# NM1500_v1 register map
File version: 1.0
Registers are 32-bit, read-write, reset 0x0 unless marked. A register's access mark holds for its fields unless they carry their own. Offsets are from the block's base; [hi:lo] are bit positions; {n}, {i} and the like mark numbered series; 'fields as' and 'values as' point back to an identical list.

## ADC — ADC Register Map
Base 0x400E0000
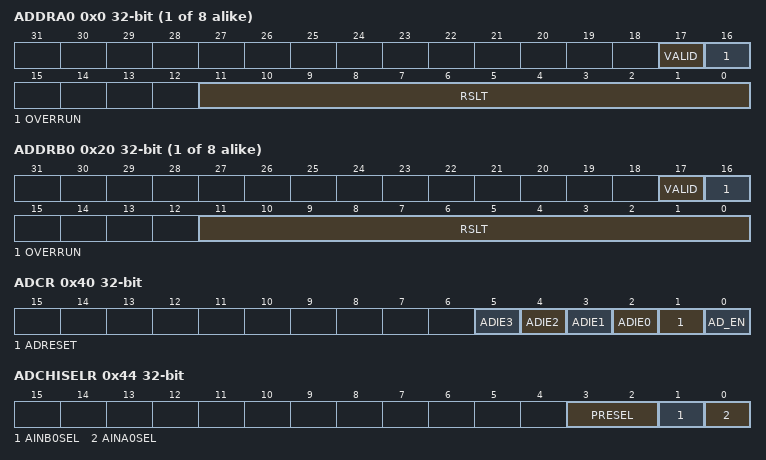
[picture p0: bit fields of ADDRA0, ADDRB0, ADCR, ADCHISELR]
{0x0+4i} ADDRA{i} ro (i=0..7) — A/D Data Register 0 for SAMPLEA0
  [17] VALID — Valid Flag. This bit is set to 1 when corresponding SAMPLE channel analog input conversion is completed and cleared by hardware after ADDR register is read.
    0=Data in RSLT[11:0] bits is not valid; 1=Data in RSLT[11:0] bits is valid
  [16] OVERRUN — Over Run Flag. If converted data in RSLT[11:0] has not been read before new conversion result is loaded to this register, OVERRUN is set to 1. It is cleared by hardware after ADDR register is read.
    0=Data in RSLT[11:0] is the recent conversion result; 1=Data in RSLT[11:0] is overwritten
  [11:0] RSLT — A/D Conversion Result. This field contains 12-bit conversion result.
{0x20+4i} ADDRB{i} ro (i=0..7) — A/D Data Register 0 for SAMPLEA0
  fields as ADDRA0
0x40 ADCR — A/D Control Register
  [n+2] ADIE{n} (n=0..3) — Specific SAMPLE A/D ADINT{n} Interrupt Enable. The A/D converter generates a conversion end ADF{n} flag in ADSR1 register upon the end of specific SAMPLE A/D conversion. If ADIE{n} bit is set then conversion end interrupt request ADINT{n} is generated.
    0=Specific SAMPLE A/D ADINT{n} interrupt function Disabled; 1=Specific SAMPLE A/D ADINT{n} interrupt function Enabled
  [1] ADRESET — ADCA, ADCB A/D Converter control circuits reset. ADRESET bit remains 1 during ADC reset, when ADC reset end, the ADRESET bit is automatically cleared to 0.
    0=Writing 0 has no effect; 1=Writing 1 will cause ADC control circuits reset to initial state, but not change the ADC registers value
  [0] AD_EN — A/D Converter Enable. Before starting the A/D conversion function, this bit should be set to 1. Clear it to 0 to disable A/D converter analog circuit power consumption.
    0=Disabled; 1=Enabled
0x44 ADCHISELR — A/D Channel Input Sources Select Register
  [3:2] PRESEL — A/D Channel AINA[7] Analog Input Selection
    0=Analog Input Channel AINA7; 1=Band-gap (VBG) Analog Input; 2=VTEMP Internal Temperature Sensor Analog Input; 3=Analog ground
  [1] AINB0SEL — A/D Channel AINB[0] Analog Input Selection
    0=AINB[0] pin P7.0/AINB0 is selected as the A/D AINB[0] input signal; 1=OP Amplifier 1 output is selected as the A/D AINB[0] input signal
  [0] AINA0SEL — A/D Channel AINA[0] Analog Input Selection
    0=AINA[0] pin P6.0/AINA0 is selected as the ADC AINA[0] input signal; 1=OP Amplifier 0 output is selected as the ADC AINA[0] input signal
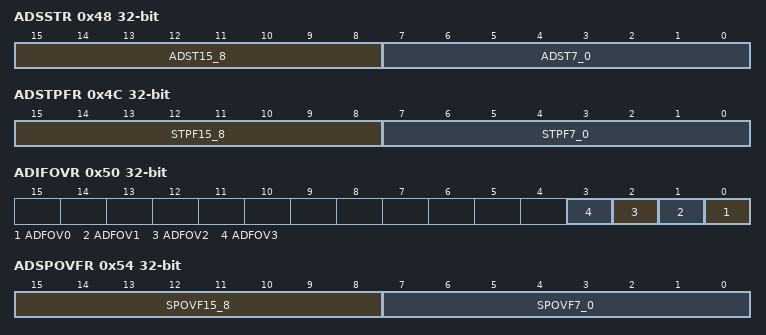
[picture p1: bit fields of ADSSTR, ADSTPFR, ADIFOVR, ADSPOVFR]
0x48 ADSSTR wo — A/D SAMPLE Software Start Register
  [15:8] ADST15_8 — A/D SAMPLEB7~0 Software Force to Start ADC Conversion Register
    0=No effect; 1=Cause an ADC conversion when the priority is given to SAMPLEB
  [7:0] ADST7_0 — A/D SAMPLEA7~0 Software Force to Start ADC Conversion Register
    0=No effect; 1=Cause an ADC conversion when the priority is given to SAMPLEA
0x4C ADSTPFR ro — A/D SAMPLE Start of Conversion Pending Flag Register
  [15:8] STPF15_8 — A/D SAMPLEB7~0 Start Conversion Pending Flag. This bit remains 1 during pending state, when the respective ADC conversion is started, the STPFx bit is automatically cleared to 0.
    0=No pending conversion for SAMPLEB; 1=SAMPLEB ADC start of conversion is pending
  [7:0] STPF7_0 — A/D SAMPLEA7~0 Start Conversion Pending Flag. This bit remains 1 during pending state, when the respective ADC conversion is started, the STPFx bit is automatically cleared to 0.
    0=There is no pending conversion for SAMPLEA; 1=SAMPLEA ADC start of conversion is pending
0x50 ADIFOVR — A/D ADINT3~0 Interrupt Flag Over Run Register
  [n] ADFOV{n} (n=0..3) — A/D ADINT{n} Interrupt flag over run bit. It is cleared by write 1.
    0=ADINT{n} interrupt flag is not overwrite to 1; 1=ADINT{n} interrupt flag is overwrite to 1
0x54 ADSPOVFR — A/D SAMPLE Start of Conversion Over Run Flag Register
  [15:8] SPOVF15_8 — A/D SAMPLEB7~0 Start Conversion Over Run Flag. It is cleared by writing 1.
    0=No SAMPLE event over run; 1=A new SAMPLEB event is generated while an old one event is pending
  [7:0] SPOVF7_0 — A/D SAMPLEA7~0 Start Conversion Over Run Flag. It is cleared by writing 1.
    0=No SAMPLE event over run; 1=A new SAMPLEA event is generated while an old one event is pending
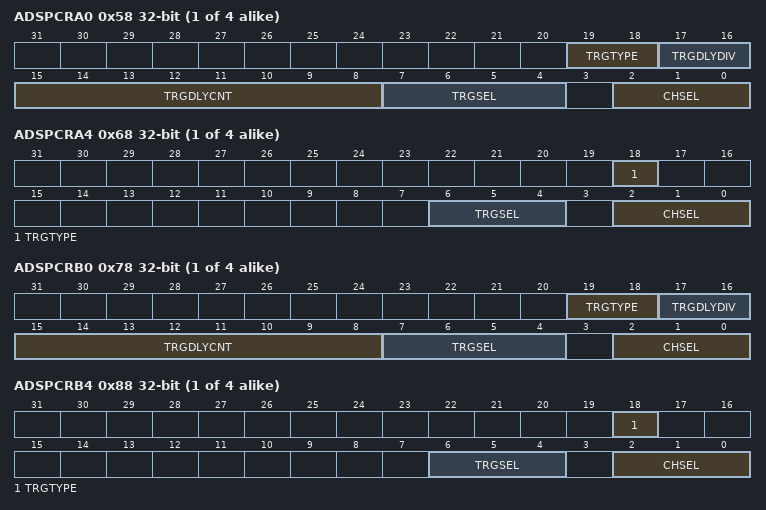
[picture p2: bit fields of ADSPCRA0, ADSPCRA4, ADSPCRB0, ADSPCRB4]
{0x58+4i} ADSPCRA{i} (i=0..3) — A/D SAMPLEA0 Control Register
  [19:18] TRGTYPE — A/D SAMPLE Trigger Type Selection
    0=Rising edge trigger; 1=Falling edge trigger; 2=PWM center-align trigger at center point (Only available when PWM is in Center-aligned mode); 3=PWM center-align trigger at period end point (Only available when PWM is in Center-aligned mode)
  [17:16] TRGDLYDIV — A/D SAMPLE Start Conversion Trigger Delay Clock Divider Selection. Trigger delay clock frequency:
    0=ADC_CLK/1; 1=ADC_CLK/2; 2=ADC_CLK/4; 3=ADC_CLK/16
  [15:8] TRGDLYCNT — A/D SAMPLE Start Conversion Trigger Delay Time
  [7:4] TRGSEL — A/D SAMPLE Start Conversion Trigger Source Selection
  [2:0] CHSEL — A/D SAMPLEA,B Channel Selection
{0x58+4i} ADSPCRA{i} (i=4..7) — A/D SAMPLEA4 Control Register
  [18] TRGTYPE — A/D SAMPLEx Trigger Type Selection
    0=Rising edge trigger; 1=Falling edge trigger
  [6:4] TRGSEL — A/D SAMPLE Start Conversion Trigger Source Selection
  [2:0] CHSEL — A/D SAMPLEA,B Channel Selection
{0x78+4i} ADSPCRB{i} (i=0..3) — A/D SAMPLEA0 Control Register
  fields as ADSPCRA0
{0x78+4i} ADSPCRB{i} (i=4..7) — A/D SAMPLEA4 Control Register
  fields as ADSPCRA4
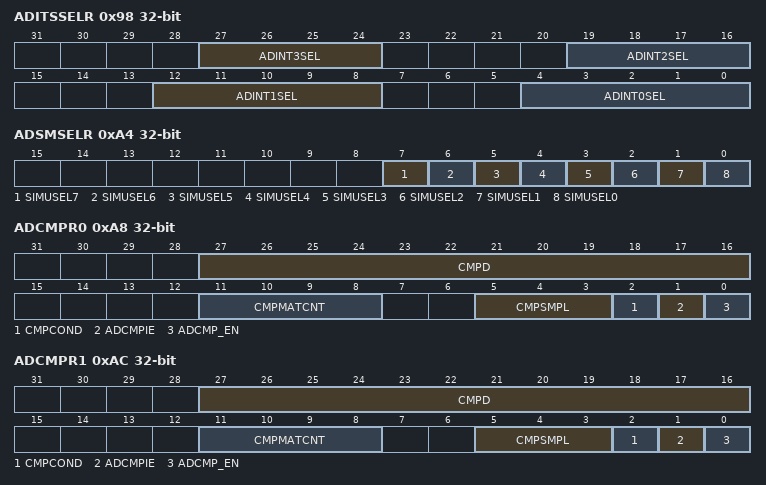
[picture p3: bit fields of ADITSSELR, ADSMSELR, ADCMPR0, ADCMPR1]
0x98 ADITSSELR — A/D Interrupt Trigger Source Select Register
  [27:24] ADINT3SEL — A/D ADINT3 Interrupt Trigger Source Selection
  [19:16] ADINT2SEL — A/D ADINT2 Interrupt Trigger Source Selection
  [12:8] ADINT1SEL — A/D ADINT1 Interrupt Trigger Source Selection
  [4:0] ADINT0SEL — A/D ADINT0 Interrupt Trigger Source Selection
0xA4 ADSMSELR — A/D SAMPLE Simultaneous Mode Select Register
  [7] SIMUSEL7 — A/D SAMPLEA7, SAMPLEB7 Simultaneous Sampling Mode Selection
    0=SAMPLEA7, SAMPLEB7 are in single sampling mode, both SAMPLEA7 and SAMPLEB7's 3 bits of CHSEL define the ADC channels to be converted; 1=SAMPLEA7, SAMPLEB7 are in simultaneous sampling mode, Only SAMPLEA7 can trigger both the ADC conversions of SAMPLEA7 and SAMPLEB7, SAMPLEB7.trigger select TRGSEL is ignored. if SAMPLEA7's CHSEL = 1, SAMPLEB7's CHSEL = 3, the pair of channels are AINA[1], AINB[3], they will do the ADC conversion at the same time
  [6] SIMUSEL6 — A/D SAMPLEA6, SAMPLEB6 Simultaneous Sampling Mode Selection
    0=SAMPLEA6, SAMPLEB6 are in single sampling mode, both SAMPLEA6 and SAMPLEB6's 3 bits of CHSEL define the ADC channels to be converted; 1=SAMPLEA6, SAMPLEB6 are in simultaneous sampling mode, Only SAMPLEA6 can trigger both the ADC conversions of SAMPLEA6 and SAMPLEB6, SAMPLEB6.trigger select TRGSEL is ignored. if SAMPLEA6's CHSEL = 1, and SAMPLEB6's CHSEL = 3, the pair of channels are AINA[1], AINB[3], they will do the ADC conversion at the same time
  [5] SIMUSEL5 — A/D SAMPLEA5, SAMPLEB5 Simultaneous Sampling Mode Selection
    0=SAMPLEA5, SAMPLEB5 are in single sampling mode, both SAMPLEA5 and SAMPLEB5's 3 bits of CHSEL define the ADC channels to be converted; 1=SAMPLEA5, SAMPLEB5 are in simultaneous sampling mode, Only SAMPLEA5 can trigger both the ADC conversions of SAMPLEA5 and SAMPLEB5, SAMPLEB5.trigger select TRGSEL is ignored. if SAMPLEA5's CHSEL = 1, and SAMPLEB5's CHSEL = 3, the pair of channels are AINA[1], AINB[3], they will do the ADC conversion at the same time
  [4] SIMUSEL4 — A/D SAMPLEA4, SAMPLEB4 Simultaneous Sampling Mode Select ion
    0=SAMPLEA4, SAMPLEB4 are in single sampling mode, both SAMPLEA4 and SAMPLEB4's 3 bits of CHSEL define the ADC channels to be converted; 1=SAMPLEA4, SAMPLEB4 are in simultaneous sampling mode, Only SAMPLEA4 can trigger both the ADC conversions of SAMPLEA4 and SAMPLEB4, SAMPLEB4.trigger select TRGSEL is ignored. if SAMPLEA4's CHSEL = 1, and SAMPLEB4's CHSEL = 3, the pair of channels are AINA[1], AINB[3], they will do the ADC conversion at the same time
  [3] SIMUSEL3 — A/D SAMPLEA3, SAMPLEB3 Simultaneous Sampling Mode Select ion
    0=SAMPLEA3, SAMPLEB3 are in single sampling mode, both SAMPLEA3 and SAMPLEB3's 3 bits of CHSEL define the ADC channels to be converted; 1=SAMPLEA3, SAMPLEB3 are in simultaneous sampling mode, Only SAMPLEA3 can trigger both the ADC conversions of SAMPLEA3 and SAMPLEB3, SAMPLEB3.trigger select TRGSEL is ignored. if SAMPLEA3's CHSEL = 1, and SAMPLEB3's CHSEL = 3, the pair of channels are AINA[1], AINB[3], they will do the ADC conversion at the same time
  [2] SIMUSEL2 — A/D SAMPLEA2, SAMPLEB2 Simultaneous Sampling Mode Selection
    0=SAMPLEA2, SAMPLEB2 are in single sampling mode, both SAMPLEA2 and SAMPLEB2's 3 bits of CHSEL define the ADC channels to be converted; 1=SAMPLEA2, SAMPLEB2 are in simultaneous sampling mode, Only SAMPLEA2 can trigger both the ADC conversions of SAMPLEA2 and SAMPLEB2, SAMPLEB2.trigger select TRGSEL is ignored. if SAMPLEA2's CHSEL = 1, and SAMPLEB2's CHSEL = 3, the pair of channels are AINA[1], AINB[3], they will do the ADC conversion at the same time
  [1] SIMUSEL1 — A/D SAMPLEA1, SAMPLEB1 Simultaneous Sampling Mode Selection
    0=SAMPLEA1, SAMPLEB1 are in single sampling mode, both SAMPLEA1 and SAMPLEB1's 3 bits of CHSEL define the ADC channels to be converted; 1=SAMPLEA1, SAMPLEB1 are in simultaneous sampling mode, Only SAMPLEA1 can trigger both the ADC conversions of SAMPLEA1 and SAMPLEB1, SAMPLEB1.trigger select TRGSEL is ignored. if SAMPLEA1's CHSEL = 1, and SAMPLEB1's CHSEL = 3, the pair of channels are AINA[1], AINB[3], they will do the ADC conversion at the same time
  [0] SIMUSEL0 — A/D SAMPLEA0, SAMPLEB0 Simultaneous Sampling Mode Selection
    0=SAMPLEA0, SAMPLEB0 are in single sampling mode, both SAMPLEA0 and SAMPLEB0's 3 bits of CHSEL define the ADC channels to be converted; 1=SAMPLEA0, SAMPLEB0 are in simultaneous sampling mode, Only SAMPLEA0 can trigger both the ADC conversions of SAMPLEA0 and SAMPLEB0, SAMPLEB0.trigger select TRGSEL is ignored. if SAMPLEA0's CHSEL = 1, and SAMPLEB0's CHSEL = 3, the pair of channels are AINA[1], AINB[3], they will do the ADC conversion at the same time
0xA8 ADCMPR0 — A/D Result Compare Register 0
  [27:16] CMPD — Comparison Data. The 12 bits data is used to compare with the conversion result of specified SAMPLE. Software can use it to monitor the external analog input pin voltage transition without imposing a load on software.
  [11:8] CMPMATCNT — Compare Match Count. When the specified A/D SAMPLE analog conversion result matches the compare condition defined by CMPCOND, the internal match counter will increase 1. When the internal counter reaches the value to (CMPMATCNT +1), the CMPF bit will be set.
  [5:3] CMPSMPL — Compare SAMPLE Selection
    {v}=SAMPLEA{v} conversion result ADDRA{v} is selected to be compared (v=0..3); {v}=SAMPLEB{v-4} conversion result ADDRB{v-4} is selected to be compared (v=4..7)
  [2] CMPCOND — Compare Condition. Note: When the internal counter reaches the value to (CMPMATCNT +1), the CMPF bit will be set.
    0=Set the compare condition as that when a 12-bit A/D conversion result is less than the 12-bit CMPD (ADCMPRx[27:16]), the internal match counter will increase one; 1=Set the compare condition as that when a 12-bit A/D conversion result is greater or equal to the 12-bit CMPD (ADCMPRx[27:16]), the internal match counter will increase one
  [1] ADCMPIE — A/D Result Compare Interrupt Enable. If the compare function is enabled and the compare condition matches the setting of CMPCOND and CMPMATCNT, ADCMPF bit will be asserted, in the meanwhile, if ADCMPIE is set to 1, a compare interrupt request is generated.
    0=Compare function interrupt Disabled; 1=Compare function interrupt Enabled
  [0] ADCMP_EN — A/D Result Compare Enable. Set this bit to 1 to enable compare CMPD[11:0] with specified SAMPLE conversion result when converted data is loaded into ADDR register.
    0=Compare Disabled; 1=Compare Enabled
0xAC ADCMPR1 — A/D Result Compare Register 0
  fields as ADCMPR0
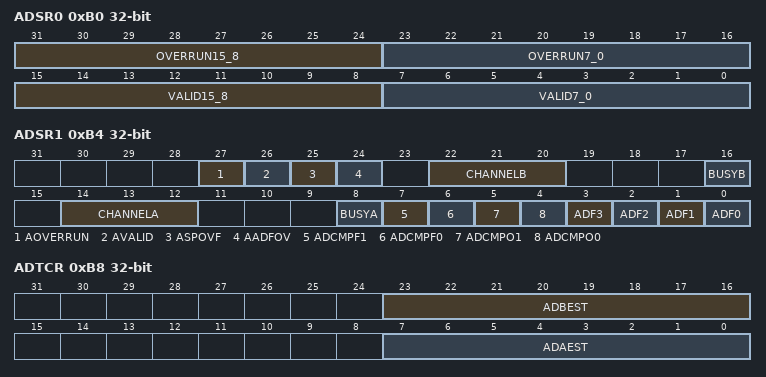
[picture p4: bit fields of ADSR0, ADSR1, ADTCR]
0xB0 ADSR0 ro — A/D Status Register 0
  [31:24] OVERRUN15_8 — ADDRB7~0 Over Run Flag. It is a mirror to OVERRUN bit in SAMPLEB A/D result data register ADDRBx
  [23:16] OVERRUN7_0 — ADDRA7~0 Over Run Flag. It is a mirror to OVERRUN bit in SAMPLEA A/D result data register ADDRAx
  [15:8] VALID15_8 — ADDRB7~0 Data Valid Flag. It is a mirror of VALID bit in SAMPLEB A/D result data register ADDRBx
  [7:0] VALID7_0 — ADDRA7~0 Data Valid Flag. It is a mirror of VALID bit in SAMPLEA A/D result data register ADDRAx
0xB4 ADSR1 — A/D Status Register 1
  [27] AOVERRUN — All SAMPLE A/D Result Data Register Over Run Flags Check. This bit will keep 1 when any OVERRUNx Flag is equal to 1.
    0=None of SAMPLE data register over run flag OVERRUNx is set to 1; 1=Any one of SAMPLE data register over run flag OVERRUNx is set to 1
  [26] AVALID — All SAMPLE A/D Result Data Register ADDR Data Valid Flag Check. This bit will keep 1 when any VALIDx Flag is equal to 1.
    0=None of SAMPLE data register valid flag VALIDx is set to 1; 1=Any one of SAMPLE data register valid flag VALIDx is set to 1
  [25] ASPOVF — All A/D SAMPLE Start Conversion Over Run Flags Check. This bit will keep 1 when any SPOVFx Flag is equal to 1.
    0=None of SAMPLE event over run flag SPOVFx is set to 1; 1=Any one of SAMPLE event over run flag SPOVFx is set to 1
  [24] AADFOV — All A/D Interrupt Flag Over Run Bits Check. This bit will keep 1 when any ADFOVx Flag is equal to 1.
    0=None of ADINT interrupt flag ADFOVx is overwritten to 1; 1=Any one of ADINT interrupt flag ADFOVx is overwritten to 1
  [22:20] CHANNELB — Current Conversion Channel
  [16] BUSYB — BUSY/IDLE. It is read only.
    0=A/D converter B (ADCB) is in idle state; 1=A/D converter B (ADCB) is busy at conversion
  [14:12] CHANNELA — Current Conversion Channel
  [8] BUSYA — BUSY/IDLE. It is read only.
    0=A/D converter A (ADCA) is in idle state; 1=A/D converter A (ADCA) is busy at conversion
  [7] ADCMPF1 — ADC Compare 1 Flag. When the specific SAMPLE A/D conversion result meets setting condition in ADCMPR1 then this bit is set to 1. And it is cleared by write 1.
    0=Conversion result in ADDR does not meet ADCMPR1 setting; 1=Conversion result in ADDR meets ADCMPR1 setting
  [6] ADCMPF0 — ADC Compare 0 Flag. When the specific SAMPLE A/D conversion result meets setting condition in ADCMPR0 then this bit is set to 1. And it is cleared by write 1.
    0=Conversion result in ADDR does not meet ADCMPR0 setting; 1=Conversion result in ADDR meets ADCMPR0 setting
  [5] ADCMPO1 — ADC Compare 1 Output Status Bit. The 12 bits compare1 data (ADCMPR1[27:16]) is used to compare with conversion result of specified SAMPLE. Software can use it to monitor the external analog input pin voltage status.
    0=Conversion result in ADDR less than ADCMPR1[27:16] setting; 1=Conversion result in ADDR great than or equal ADCMPR1[27:16] setting
  [4] ADCMPO0 — ADC Compare 0 Output Status Bit. The 12 bits compare0 data (ADCMPR0[27:16]) is used to compare with conversion result of specified SAMPLE. Software can use it to monitor the external analog input pin voltage status.
    0=Conversion result in ADDR is less than ADCMPR0[27:16] setting; 1=Conversion result in ADDR is great than or equal ADCMPR0[27:16] setting
  [3] ADF3 — A/D ADINT3 Interrupt Flag. It is cleared by writing 1. This bit indicates whether an A/D conversion of specific SAMPLE has been completed
    0=No ADINT3 interrupt pulse received; 1=ADINT3 interrupt pulse received
  [2] ADF2 — A/D ADINT2 Interrupt Flag. It is cleared by writing 1. This bit indicates whether an A/D conversion of specific SAMPLE has been completed.
    0=No ADINT2 interrupt pulse received; 1=ADINT2 interrupt pulse received
  [1] ADF1 — A/D ADINT1 Interrupt Flag. It is cleared by writing 1. This bit indicates whether an A/D conversion of specific SAMPLE has been completed.
    0=no ADINT1 interrupt pulse received; 1=ADINT1 interrupt pulse has been received
  [0] ADF0 — A/D ADINT0 Interrupt Flag. It is cleared by writing 1. This bit indicates whether an A/D conversion of specific SAMPLE has been completed.
    0=No ADINT0 interrupt pulse received; 1=ADINT0 interrupt pulse received
0xB8 ADTCR — A/D Timing Control Register
  [23:16] ADBEST — ADCB Extend Sampling Time. When A/D converting at high conversion rate, the sampling time of analog input voltage may not enough if input channel loading is heavy, SW can extend A/D sampling time after trigger source is coming to get enough sampling time. The range of start delay time is from 0~255 ADC clock.
  [7:0] ADAEST — ADCA Extend Sampling Time. When A/D converting at high conversion rate, the sampling time of analog input voltage may not enough if input channel loading is heavy, SW can extend A/D sampling time after trigger source is coming to get enough sampling time. The range of start delay time is from 0~255 ADC clock.
